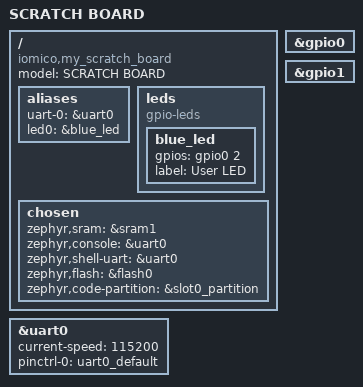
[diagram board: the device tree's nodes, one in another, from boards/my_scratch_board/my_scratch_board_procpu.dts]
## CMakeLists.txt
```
cmake_minimum_required(VERSION 3.20.0)

list(APPEND BOARD_ROOT ${CMAKE_CURRENT_SOURCE_DIR})
list(APPEND DTS_ROOT ${CMAKE_CURRENT_SOURCE_DIR}/..)

find_package(Zephyr REQUIRED)
project(my_zephyr_app)

target_sources(app PRIVATE src/main.cpp)
add_subdirectory(drivers/led_driver)
```

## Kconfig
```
menuconfig LED_SUBSYSTEM
	bool "LED Subsystem"
	default y

if LED_SUBSYSTEM

	config APP_HEARTBEAT_PERIOD_MS
		int "Led 0 Time period (100-2000)"
		range 100 2000
		default 500

	choice
		prompt "LED blink sleep time"
		default BLINK_SLEEP_1000MS
	
	config BLINK_SLEEP_250MS
		bool "1/4 s Fast"

	config BLINK_SLEEP_1000MS
		bool "1s Normal"

	config BLINK_SLEEP_2000MS
		bool "2s Slow"

	endchoice


	config BLINK_SLEEP_TIME_MS
		int
		default 250 if BLINK_SLEEP_250MS
		default 1000 if BLINK_SLEEP_1000MS
		default 2000 if BLINK_SLEEP_2000MS
		default 0


	menuconfig LED_ADVANCED_SETTING
		bool "Advance LED Setting"
		default y

	if LED_ADVANCED_SETTING
	
	
		config LED_BRIGHTNESS
			int "LED brightness (0-100)"
			range 0 100
			default 100

		config LED_FADE_DURATION_MS
			int "Fade duration (ms)"
			range 0 5000
			default 500

	
		menu "Expert settings"

			config LED_DEBUG
				bool "Enable led debugging"	
				default n
		
			config CUSTOM_PATTERN
				bool "Custom blink pattern"
				default n

		endmenu
			
	endif # LED_ADVANCED_SETTING

endif # LED_SUBSYSTEM

	

source "Kconfig.zephyr"
rsource "drivers/led_driver/Kconfig"
```

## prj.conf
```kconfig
CONFIG_GPIO=y
CONFIG_LOG=y
CONFIG_BLINK_SLEEP_250MS=y
CONFIG_LED_DRIVER=y
CONFIG_SHELL=y
```

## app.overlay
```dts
/{
	aliases{
		app-led = &blue_led;
	};

	led_driver0: led_driver{
		compatible = "led,driver";
		status = "okay";
		gpios = <&gpio0 15 GPIO_ACTIVE_LOW>;
	};


};
```

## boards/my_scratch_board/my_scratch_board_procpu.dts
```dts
/dts-v1/;

#include <espressif/esp32/esp32_wroom_32ue_n4.dtsi>
#include "doit_esp32_devkit_v1-pinctrl.dtsi"
#include <zephyr/dt-bindings/input/input-event-codes.h>
#include <zephyr/dt-bindings/input/esp32-touch-sensor-input.h>
#include <espressif/partitions_0x1000_amp.dtsi>

/ {
	model = "SCRATCH BOARD";
	compatible = "iomico,my_scratch_board";

	aliases {
		uart-0 = &uart0;
		led0 = &blue_led;
	};

	leds {
		compatible = "gpio-leds";

		blue_led: blue_led {
			gpios = <&gpio0 2 GPIO_ACTIVE_HIGH>;
			label = "User LED";
		};
	};


	chosen {
		zephyr,sram = &sram1;
		zephyr,console = &uart0;
		zephyr,shell-uart = &uart0;
		zephyr,flash = &flash0;
		zephyr,code-partition = &slot0_partition;
	};
};

&uart0 {
	status = "okay";
	current-speed = <115200>;
	pinctrl-0 = <&uart0_default>;
	pinctrl-names = "default";
};

&gpio0 {
	status = "okay";
};

&gpio1 {
	status = "okay";
};
```

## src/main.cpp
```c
#include <zephyr/drivers/gpio.h>
#include <zephyr/kernel.h>
#include <zephyr/logging/log.h>
#include <zephyr/drivers/sensor.h>
#include "../drivers/led_driver/led_driver.h"


/* The devicetree node identifier for the "led0" alias. */
/* First it will look to app.overlay */

#define LED_NODE DT_ALIAS(app_led)

static const struct gpio_dt_spec led = GPIO_DT_SPEC_GET(LED_NODE, gpios);

LOG_MODULE_REGISTER(main, LOG_LEVEL_INF);

namespace {
        int i=0;
	void test () {
		const struct device* driver = DEVICE_DT_GET(DT_NODELABEL(led_driver0));
		struct sensor_value val;
		auto ret = sensor_sample_fetch(driver);
		LOG_INF("Sample fetch ret %d", ret);
		led_driver_set_state(driver, i);
		i++;
		
		k_msleep(500);
		
		ret = sensor_channel_get(driver, SENSOR_CHAN_AMBIENT_TEMP, &val);
		LOG_INF("Channel ret %d", ret);
		led_driver_set_state(driver, i);
		i++;
		
		k_msleep(500);     
	}
}

int main(void)
{
   
   /* Blue led with Zephir driver*/
   
   
   bool led_state = true;
    if (!gpio_is_ready_dt(&led)) return 0;
    if (gpio_pin_configure_dt(&led, GPIO_OUTPUT_ACTIVE) < 0) return 0;
    
    

    while (1) {
    
    test();
    
     /* Blue led with Zephir driver*/
      
        if (gpio_pin_toggle_dt(&led) < 0) return 0;

        led_state = !led_state;
        LOG_INF("LED state: %s", led_state ? "ON" : "OFF");
        k_msleep(CONFIG_APP_HEARTBEAT_PERIOD_MS);   
    }   
    
   
    return 0;
}
```
